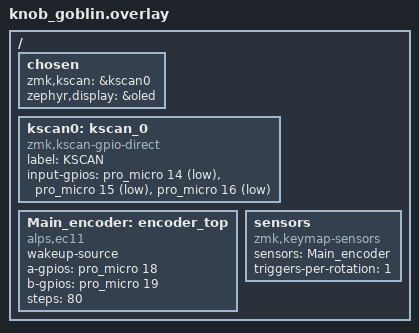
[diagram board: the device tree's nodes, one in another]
/*
 * Copyright (c) 2022 The ZMK Contributors
 *
 * SPDX-License-Identifier: MIT
 */

#include <dt-bindings/zmk/matrix_transform.h>

/ {
	chosen {
		zmk,kscan = &kscan0;
		zephyr,display = &oled;
	};

	kscan0: kscan_0 {
		compatible = "zmk,kscan-gpio-direct";

		label = "KSCAN";

		input-gpios
			= <&pro_micro 14 (GPIO_ACTIVE_LOW | GPIO_PULL_UP)>
            , <&pro_micro 15 (GPIO_ACTIVE_LOW | GPIO_PULL_UP)>
            , <&pro_micro 16 (GPIO_ACTIVE_LOW | GPIO_PULL_UP)>
			;
	};


    Main_encoder: encoder_top {
        compatible = "alps,ec11";
        wakeup-source;
        a-gpios = <&pro_micro 18 (GPIO_ACTIVE_HIGH | GPIO_PULL_UP)>;
        b-gpios = <&pro_micro 19 (GPIO_ACTIVE_HIGH | GPIO_PULL_UP)>;
        steps = <80>;
        status = "okay";
    };

    sensors: sensors {
        compatible = "zmk,keymap-sensors";
        sensors = <&Main_encoder>;
        triggers-per-rotation = <1>;
    };
};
